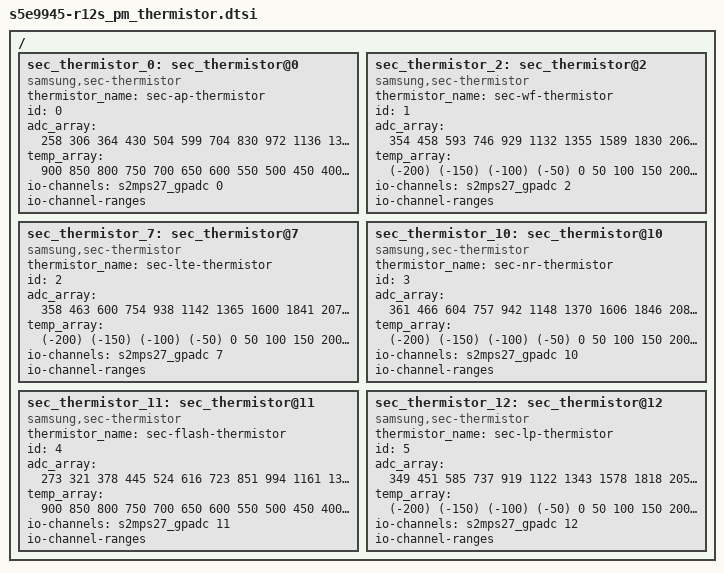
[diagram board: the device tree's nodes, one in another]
/*
 * SAMSUNG S5E9945 Power Management device tree source
 *
 * Copyright (c) 2024 Samsung Electronics Co., Ltd.
 *		http://www.samsung.com
 *
 * This program is free software; you can redistribute it and/or modify
 * it under the terms of the GNU General Public License version 2 as
 * published by the Free Software Foundation.
 */

/ {
	fragment@model {
		target-path = "/";
		__overlay__ {
			sec_thermistor_0: sec_thermistor@0 {
				compatible = "samsung,sec-thermistor";
				status = "okay";
				thermistor_name = "sec-ap-thermistor";
				id = <0>;

				adc_array = <258 306 364 430 504 599 704 830 972 1136
					1317 1513 1731 1962 2196 2438 2673 2899 3108 3287
					3451 3588 3694>;

				temp_array = <900 850 800 750 700 650 600 550 500 450
					  400 350 300 250 200 150 100 50 0 (-50)
					  (-100) (-150) (-200)>;

				io-channels = <&s2mps27_gpadc 0>;
				io-channel-names = "adc-ap-temp";
				io-channel-ranges;
			};

			sec_thermistor_2: sec_thermistor@2 {
				compatible = "samsung,sec-thermistor";
				status = "okay";
				thermistor_name = "sec-wf-thermistor";
				id = <1>;

				adc_array = <354 458 593 746 929 1132 1355 1589 1830 2066
					2298 2519 2724 2911 3081 3225 3356 3464 3558 3639
					3707 3765 3814>;

				temp_array = <(-200) (-150) (-100) (-50) 0 50 100 150 200 250
					300 350 400 450 500 550 600 650 700 750
					800 850 900>;

				io-channels = <&s2mps27_gpadc 2>;
				io-channel-names = "adc-wf-temp";
				io-channel-ranges;
			};

			sec_thermistor_7: sec_thermistor@7 {
				compatible = "samsung,sec-thermistor";
				status = "okay";
				thermistor_name = "sec-lte-thermistor";
				id = <2>;

				adc_array = <358 463 600 754 938 1142 1365 1600 1841 2077
					2311 2528 2733 2920 3089 3234 3363 3470 3563 3644
					3711 3770 3818>;

				temp_array = <(-200) (-150) (-100) (-50) 0 50 100 150 200 250
					300 350 400 450 500 550 600 650 700 750
					800 850 900>;

				io-channels = <&s2mps27_gpadc 7>;
				io-channel-names = "adc-lte-temp";
				io-channel-ranges;
			};

			sec_thermistor_10: sec_thermistor@10 {
				compatible = "samsung,sec-thermistor";
				status = "okay";
				thermistor_name = "sec-nr-thermistor";
				id = <3>;

				adc_array = <361 466 604 757 942 1148 1370 1606 1846 2083
					2316 2533 2738 2923 3092 3236 3365 3472 3565 3645
					3712 3770 3819>;

				temp_array = <(-200) (-150) (-100) (-50) 0 50 100 150 200 250
					300 350 400 450 500 550 600 650 700 750
					800 850 900>;

				io-channels = <&s2mps27_gpadc 10>;
				io-channel-names = "adc-nr-temp";
				io-channel-ranges;
			};

			sec_thermistor_11: sec_thermistor@11 {
				compatible = "samsung,sec-thermistor";
				status = "okay";
				thermistor_name = "sec-flash-thermistor";
				id = <4>;

				adc_array = <273 321 378 445 524 616 723 851 994 1161
					1344 1546 1763 1994 2229 2469 2704 2928 3134 3312
					3469 3604 3706>;

				temp_array = <900 850 800 750 700 650 600 550 500 450
					  400 350 300 250 200 150 100 50 0 (-50)
					  (-100) (-150) (-200)>;

				io-channels = <&s2mps27_gpadc 11>;
				io-channel-names = "adc-flash-temp";
				io-channel-ranges;
			};

			sec_thermistor_12: sec_thermistor@12 {
				compatible = "samsung,sec-thermistor";
				status = "okay";
				thermistor_name = "sec-lp-thermistor";
				id = <5>;

				adc_array = <349 451 585 737 919 1122 1343 1578 1818 2055
					2285 2509 2715 2903 3074 3221 3350 3459 3553 3634
					3703 3761 3810>;

				temp_array = <(-200) (-150) (-100) (-50) 0 50 100 150 200 250
					300 350 400 450 500 550 600 650 700 750
					800 850 900>;

				io-channels = <&s2mps27_gpadc 12>;
				io-channel-names = "adc-lp-temp";
				io-channel-ranges;
			};
		}; /* end of __overlay__ */
	}; /* end of fragment */
}; /* end of root */
